# RZN2H register map
Vendor: Renesas Electronics Corporation; Series: RZN; File version: 1.00.00
CPU: other r0p0, little endian, MPU, no FPU, VTOR, 4 interrupt priority bits, 624 interrupts
Registers are 32-bit, read-write, reset 0x0 unless marked. A register's access mark holds for its fields unless they carry their own. Offsets are from the block's base; [hi:lo] are bit positions; lines under a group give offsets from that group; {n}, {i} and the like mark numbered series; 'fields as' and 'values as' point back to an identical list.

## PORT_SRN — I/O Ports (Safety region N)
Base 0x802B0000
Same registers: PORT_SRS 0x812C0000
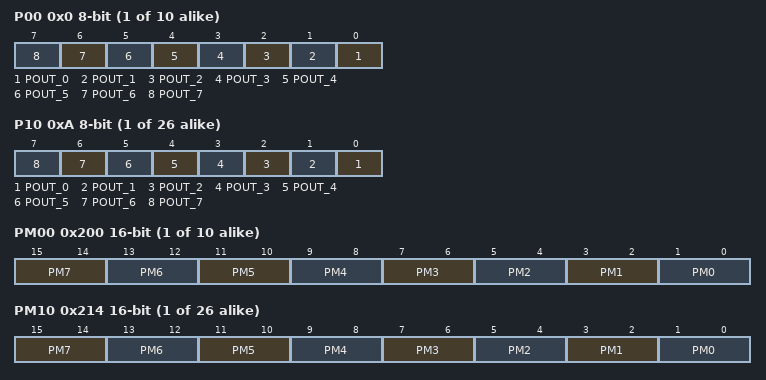
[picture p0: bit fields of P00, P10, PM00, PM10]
{0x0+i} P0{i} (i=0..9) 8-bit — Port {i} Register
  [all] fields
    0=Low output; 1=High output
  [n] POUT_{n} (n=0..7) — Pm_n Output Data Store (n: bit position)
{0x0+i} P{i} (i=10..35) 8-bit — Port {i} Register
  fields as P00
{0x200+2i} PM0{i} (i=0..9) 16-bit — Port {i} Mode Register
  [2n+1:2n] PM{n} (n=1..7) — Pm_{n} I/O Select
  [1:0] PM0 — Pm_0 I/O Select
    0=Hi-Z; 1=Input; 2=Output (Output data is not input to input buffer); 3=Output (Output data is input to input buffer)
{0x200+2i} PM{i} (i=10..35) 16-bit — Port {i} Mode Register
  fields as PM00
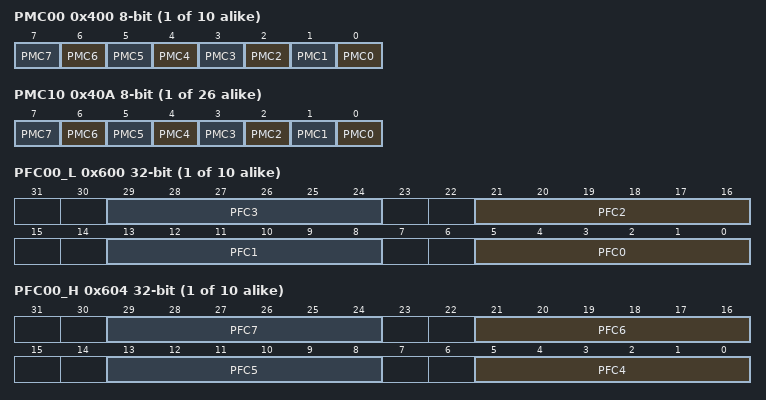
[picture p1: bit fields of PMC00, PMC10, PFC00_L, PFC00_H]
{0x400+i} PMC0{i} (i=0..9) 8-bit — Port {i} Mode Control Register
  [all] fields
    0=Uses the pin as a general I/O pin; 1=Uses the pin as an I/O port for peripheral functions
  [n] PMC{n} (n=0..7) — Pm_n Pin Mode Control (n: bit position)
{0x400+i} PMC{i} (i=10..35) 8-bit — Port {i} Mode Control Register
  fields as PMC00
{0x600+8i} PFC0{i}_L (i=0..9) — Port {i} Function Control Register
  [8n+5:8n] PFC{n} (n=0..3) — Pm_{n} Pin function Select
{0x604+8i} PFC0{i}_H (i=0..9) — Port {i} Function Control Register
  [8n-27:8n-32] PFC{n} (n=4..7) — Pm_{n} Pin function Select
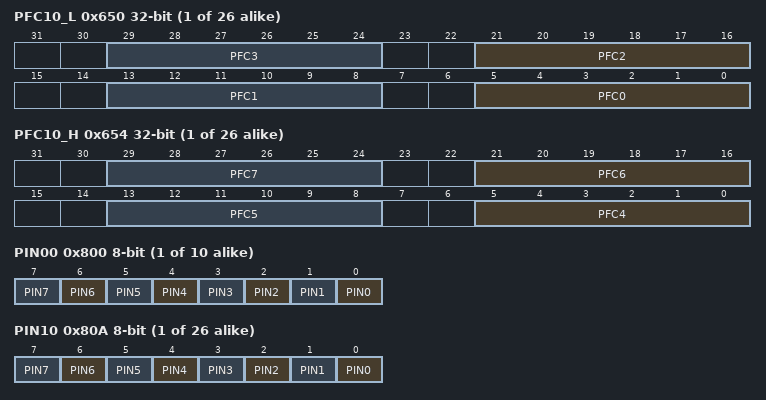
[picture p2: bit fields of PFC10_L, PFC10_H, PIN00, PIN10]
{0x600+8i} PFC{i}_L (i=10..35) — Port {i} Function Control Register
  [8n+5:8n] PFC{n} (n=0..3) — Pm_{n} Pin function Select
{0x604+8i} PFC{i}_H (i=10..35) — Port {i} Function Control Register
  [8n-27:8n-32] PFC{n} (n=4..7) — Pm_{n} Pin function Select
{0x800+i} PIN0{i} (i=0..9) 8-bit ro — Port {i} Input Register
  [all] fields
    0=Low input; 1=High input
  [n] PIN{n} (n=0..7) — Pm_n Pin Input (n: bit position)
{0x800+i} PIN{i} (i=10..35) 8-bit ro — Port {i} Input Register
  fields as PIN00
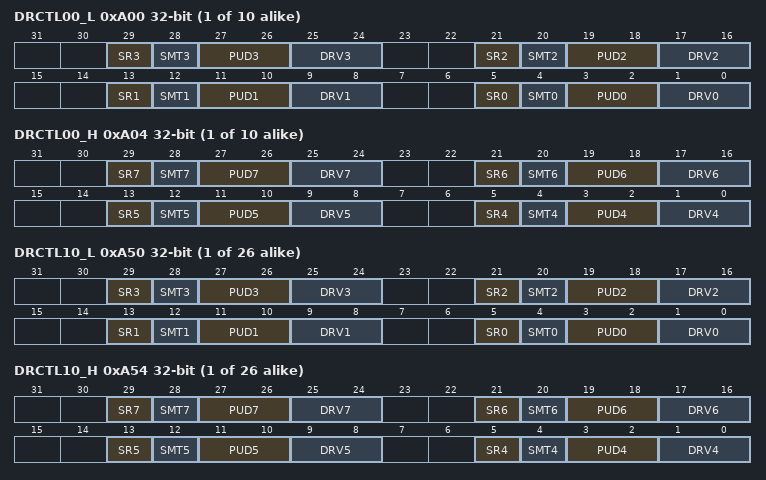
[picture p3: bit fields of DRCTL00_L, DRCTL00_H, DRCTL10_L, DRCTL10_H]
{0xA00+8i} DRCTL0{i}_L (i=0..9) — I/O Buffer {i} Function Switching Register
  [29] SR3 — Pm_3 Slew Rate Control
  [28] SMT3 — Pm_3 Schmitt Trigger Control
  [27:26] PUD3 — Pm_3 Pull-Up/Down Control
  [25:24] DRV3 — Pm_3 Driving Ability Control
  [21] SR2 — Pm_2 Slew Rate Control
  [20] SMT2 — Pm_2 Schmitt Trigger Control
  [19:18] PUD2 — Pm_2 Pull-Up/Down Control
  [17:16] DRV2 — Pm_2 Driving Ability Control
  [13] SR1 — Pm_1 Slew Rate Control
  [12] SMT1 — Pm_1 Schmitt Trigger Control
  [11:10] PUD1 — Pm_1 Pull-Up/Down Control
  [9:8] DRV1 — Pm_1 Driving Ability Control
  [5] SR0 — Pm_0 Slew Rate Control
    0=Slow; 1=Fast
  [4] SMT0 — Pm_0 Schmitt Trigger Control
    0=Disable Schmitt Trigger input; 1=Enable Schmitt Trigger input
  [3:2] PUD0 — Pm_0 Pull-Up/Down Control
    0=No pull-up/down; 1=Pull-up; 2=Pull-down; 3=Setting prohibited
  [1:0] DRV0 — Pm_0 Driving Ability Control
    0=Low; 1=Middle; 2=High; 3=Ultra High
{0xA04+8i} DRCTL0{i}_H (i=0..9) — I/O Buffer {i} Function Switching Register
  [29] SR7 — Pm_7 Slew Rate Control
  [28] SMT7 — Pm_7 Schmitt Trigger Control
  [27:26] PUD7 — Pm_7 Pull-Up/Down Control
  [25:24] DRV7 — Pm_7 Driving Ability Control
  [21] SR6 — Pm_6 Slew Rate Control
  [20] SMT6 — Pm_6 Schmitt Trigger Control
  [19:18] PUD6 — Pm_6 Pull-Up/Down Control
  [17:16] DRV6 — Pm_6 Driving Ability Control
  [13] SR5 — Pm_5 Slew Rate Control
  [12] SMT5 — Pm_5 Schmitt Trigger Control
  [11:10] PUD5 — Pm_5 Pull-Up/Down Control
  [9:8] DRV5 — Pm_5 Driving Ability Control
  [5] SR4 — Pm_4 Slew Rate Control
    0=Slow; 1=Fast
  [4] SMT4 — Pm_4 Schmitt Trigger Control
    values as DRCTL00_L.SMT0
  [3:2] PUD4 — Pm_4 Pull-Up/Down Control
    values as DRCTL00_L.PUD0
  [1:0] DRV4 — Pm_4 Driving Ability Control
    0=Low; 1=Middle; 2=High; 3=Ultra High
{0xA00+8i} DRCTL{i}_L (i=10..35) — I/O Buffer {i} Function Switching Register
  fields as DRCTL00_L
{0xA04+8i} DRCTL{i}_H (i=10..35) — I/O Buffer {i} Function Switching Register
  fields as DRCTL00_H
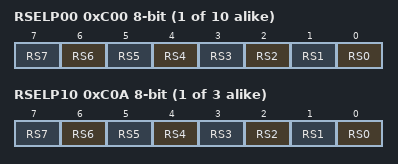
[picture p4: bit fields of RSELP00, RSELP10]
{0xC00+i} RSELP0{i} (i=0..9) 8-bit — Port {i} Region Select Register
  [all] fields
    0=Safety region (Address is 0x812C_0xxx); 1=Non safety region (Address is 0x802B_0xxx)
  [n] RS{n} (n=0..7) — Pm_n pin I/O port registers Region Select (n = bit position)
{0xC00+i} RSELP{i} (i=10..12) 8-bit — Port {i} Region Select Register
  fields as RSELP00
{0x1000+i} SLPORT{i} (i=0..35) 8-bit — Port {i} Access Control Register
  [1:0] SL
    {v}=Security Level {v} (v=0..3)
0x1C00 SLRSELP 8-bit — RSELP Access Control Register
  [1:0] SL
    {v}=Security Level {v} (v=0..3)
0x1F00 SLPSR reset 0x3 — Port Security Register Access Control Register
  [1:0] SL
    {v}=Security Level {v} (v=0..3)
0x1F04 RSELPSR 8-bit — Port Security Register Access Region Select Register
  [0] RS
    0=Safety region (Address is 0x812C_1xxx); 1=Non-safety region (Address is 0x802B_1xxx)

## PORT_NSR — I/O Ports (Non safety region)
Base 0x802C0000
Registers as PORT_SRN, without RSELP0*, RSELP*, SLRSELP, SLPSR, RSELPSR; these are added or differ:
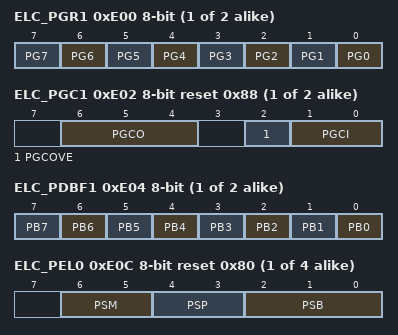
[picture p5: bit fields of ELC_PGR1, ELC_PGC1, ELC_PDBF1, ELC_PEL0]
{0xDFF+i} ELC_PGR{i} (i=1..2) 8-bit — ELC Port Group Setting Register {i}
  [all] fields
    0=The port bit is not specified as a member of the same group; 1=The port bit is specified as a member of the same group
  [n] PG{n} (n=0..7) — Port Group Setting
{0xE01+i} ELC_PGC{i} (i=1..2) 8-bit reset 0x88 — ELC Port Group Control Register {i}
  [6:4] PGCO — Port Group Operation Select
    0=0 is output when the event is input; 1=1 is output when the event is input; 2=The toggled (inverted) value is output when the event is input. The target Port m Mode register should be set to 11b: Output (Output data is input to input buffer); 3=The buffer value is output when the event is input; 0b1xx=Setting prohibited
  [2] PGCOVE — PDBF Overwrite
    0=Overwriting ELC_PDBFn register is disabled; 1=Overwriting ELC_PDBFn register is enabled
  [1:0] PGCI — Event Output Edge Select
    0=Event is generated on detection of the rising edge of the external input signal; 1=Event is generated on detection of the falling edge of the external input signal; 0b1x=Event is generated on detection of both the rising and falling edges of the external input signal
{0xE00+4i} ELC_PDBF{i} (i=1..2) 8-bit — ELC Port Buffer Register {i}
  [n] PB{n} (n=0..7) — Port Buffer {n}
{0xE0C+i} ELC_PEL{i} (i=0..3) 8-bit reset 0x80 — ELC Port Setting Register {i}
  [6:5] PSM — Event Link Specification
    0=For the output port, 0 is output when the event is input. For the input port, the event is output on detection of the rising edge.; 1=For the output port, 1 is output when the event is input. For the input port, the event is output on detection of the falling edge.; 0b1x=For the output port, the toggled (inverted) value is output when the event is input. For the input port, the event is output on detection of both the rising and falling edges. The target Port m Mode register should be set to 11b: Output (Output data is input to input buffer)
  [4:3] PSP — Port Number Specification
    0=Setting prohibited; 1=Port 14 (corresponding to ELC_PGR1); 2=Port 30 (corresponding to ELC_PGR2); 3=Setting prohibited
  [2:0] PSB — Bit Number Specification
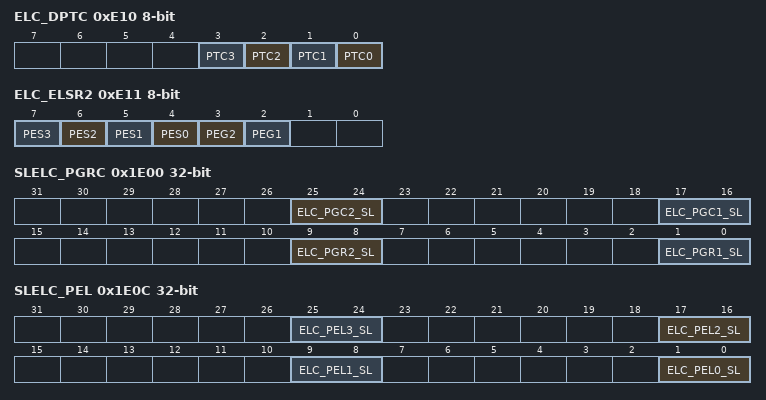
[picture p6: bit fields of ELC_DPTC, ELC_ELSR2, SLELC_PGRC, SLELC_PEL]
0xE10 ELC_DPTC 8-bit — ELC Edge Detection Control Register
  [all] fields
    0=Disable edge detection for Single Input Port n; 1=Enable edge detection for Single Input Port n
  [n] PTC{n} (n=0..3) — Single Input Port n Edge Detection
0xE11 ELC_ELSR2 8-bit — ELC Port Event Control Register
  [n+4] PES{n} (n=0..3) — Single Port n Event Link Function Enable
    0=Disable Single Port event link function; 1=Enable Single Port event link function
  [3] PEG2 — ELC Port Buffer Register (ELC_PDBFn) write access control. When set to 1, writing to the ELC_PDBFn register via Internal peripheral bus is disabled, preventing overwriting.
    0=When not use event link function of input port group n; 1=When use event link function of input port group n
  [2] PEG1 — ELC Port Buffer Register (ELC_PDBFn) write access control. When set to 1, writing to the ELC_PDBFn register via Internal peripheral bus is disabled, preventing overwriting.
    values as PEG2
0x1E00 SLELC_PGRC — ELC_PGR/ELC_PGC Security Level Register
  [25:24] ELC_PGC2_SL, [17:16] ELC_PGC1_SL, [9:8] ELC_PGR2_SL, [1:0] ELC_PGR1_SL
{0x1E00+4i} SLELC_PDBF{i} (i=1..2) — ELC_PDBFn Security Level Register {i}
  [1:0] ELC_PDBF_SL
0x1E0C SLELC_PEL — ELC_PEL Security Level Register
  [8n+1:8n] ELC_PEL{n}_SL (n=0..3)
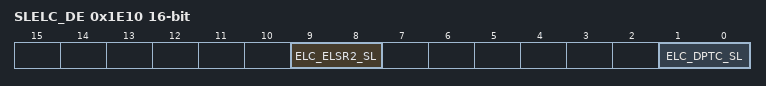
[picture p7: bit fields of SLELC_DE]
0x1E10 SLELC_DE 16-bit — ELC_DPTC/ELC_ELSR2 Security Level Register
  [9:8] ELC_ELSR2_SL — ELC_ELSR2 register Security Level
  [1:0] ELC_DPTC_SL — ELC_DPTC register Security Level
0x1F00 SLPSRNS reset 0x3 — Port NS Security Register Access Control Register
  [1:0] SL
    {v}=Security Level {v} (v=0..3)
